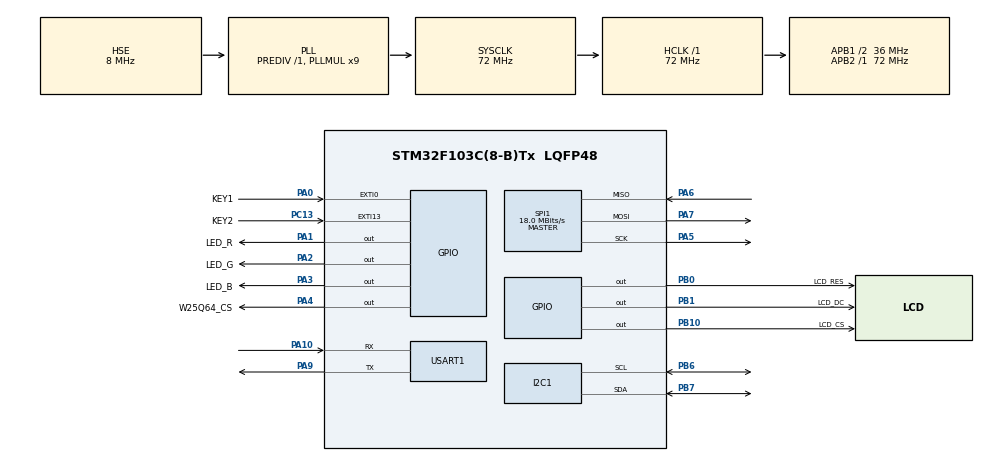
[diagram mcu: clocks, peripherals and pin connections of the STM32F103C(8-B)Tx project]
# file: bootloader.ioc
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Dma.Request0=SPI1_RX
Dma.Request1=SPI1_TX
Dma.SPI1_RX.0.Direction=DMA_PERIPH_TO_MEMORY
Dma.SPI1_RX.0.Instance=DMA1_Channel2
Dma.SPI1_RX.0.MemDataAlignment=DMA_MDATAALIGN_BYTE
Dma.SPI1_RX.0.MemInc=DMA_MINC_ENABLE
Dma.SPI1_RX.0.Mode=DMA_NORMAL
Dma.SPI1_RX.0.PeriphDataAlignment=DMA_PDATAALIGN_BYTE
Dma.SPI1_RX.0.PeriphInc=DMA_PINC_DISABLE
Dma.SPI1_RX.0.Priority=DMA_PRIORITY_LOW
Dma.SPI1_TX.1.Direction=DMA_MEMORY_TO_PERIPH
Dma.SPI1_TX.1.Instance=DMA1_Channel3
Dma.SPI1_TX.1.MemDataAlignment=DMA_MDATAALIGN_BYTE
Dma.SPI1_TX.1.MemInc=DMA_MINC_ENABLE
Dma.SPI1_TX.1.Mode=DMA_NORMAL
Dma.SPI1_TX.1.PeriphDataAlignment=DMA_PDATAALIGN_BYTE
Dma.SPI1_TX.1.PeriphInc=DMA_PINC_DISABLE
Dma.SPI1_TX.1.Priority=DMA_PRIORITY_LOW
Mcu.Family=STM32F1
Mcu.Name=STM32F103C(8-B)Tx
Mcu.Package=LQFP48
NVIC.DMA1_Channel2_IRQn=true\:0\:0\:false\:false\:true\:false\:true\:true
NVIC.DMA1_Channel3_IRQn=true\:0\:0\:false\:false\:true\:false\:true\:true
NVIC.EXTI0_IRQn=true\:0\:0\:false\:false\:true\:true\:true\:true
NVIC.EXTI15_10_IRQn=true\:0\:0\:false\:false\:true\:true\:true\:true
NVIC.PriorityGroup=NVIC_PRIORITYGROUP_4
NVIC.SPI1_IRQn=true\:0\:0\:false\:false\:true\:true\:true\:true
NVIC.USART1_IRQn=true\:0\:0\:false\:false\:true\:true\:true\:true
PA0-WKUP.GPIO_Label=KEY1
PA0-WKUP.Signal=GPXTI0
PA1.GPIO_Label=LED_R
PA1.GPIO_PuPd=GPIO_NOPULL
PA1.GPIO_Speed=GPIO_SPEED_FREQ_LOW
PA1.PinState=GPIO_PIN_SET
PA1.Signal=GPIO_Output
PA10.Mode=Asynchronous
PA10.Signal=USART1_RX
PA13.Mode=Serial_Wire
PA13.Signal=SYS_JTMS-SWDIO
PA14.Mode=Serial_Wire
PA14.Signal=SYS_JTCK-SWCLK
PA2.GPIO_Label=LED_G
PA2.PinState=GPIO_PIN_SET
PA2.Signal=GPIO_Output
PA3.GPIO_Label=LED_B
PA3.PinState=GPIO_PIN_SET
PA3.Signal=GPIO_Output
PA4.GPIO_Label=W25Q64_CS
PA4.GPIO_Speed=GPIO_SPEED_FREQ_HIGH
PA4.PinState=GPIO_PIN_SET
PA4.Signal=GPIO_Output
PA5.Mode=Full_Duplex_Master
PA5.Signal=SPI1_SCK
PA6.Mode=Full_Duplex_Master
PA6.Signal=SPI1_MISO
PA7.Mode=Full_Duplex_Master
PA7.Signal=SPI1_MOSI
PA9.Mode=Asynchronous
PA9.Signal=USART1_TX
PB0.GPIO_Label=LCD_RES
PB0.Signal=GPIO_Output
PB1.GPIO_Label=LCD_DC
PB1.Signal=GPIO_Output
PB10.GPIO_Label=LCD_CS
PB10.GPIO_Speed=GPIO_SPEED_FREQ_HIGH
PB10.PinState=GPIO_PIN_SET
PB10.Signal=GPIO_Output
PB6.Mode=I2C
PB6.Signal=I2C1_SCL
PB7.Mode=I2C
PB7.Signal=I2C1_SDA
PC13-TAMPER-RTC.GPIO_Label=KEY2
PC13-TAMPER-RTC.Signal=GPXTI13
PC14-OSC32_IN.Mode=LSE-External-Oscillator
PC14-OSC32_IN.Signal=RCC_OSC32_IN
PC15-OSC32_OUT.Mode=LSE-External-Oscillator
PC15-OSC32_OUT.Signal=RCC_OSC32_OUT
PD0-OSC_IN.Mode=HSE-External-Oscillator
PD0-OSC_IN.Signal=RCC_OSC_IN
PD1-OSC_OUT.Mode=HSE-External-Oscillator
PD1-OSC_OUT.Signal=RCC_OSC_OUT
ProjectManager.HeapSize=0x200
ProjectManager.StackSize=0x400
ProjectManager.TargetToolchain=MDK-ARM V5.32
RCC.AHBFreq_Value=72000000
RCC.APB1CLKDivider=RCC_HCLK_DIV2
RCC.APB1Freq_Value=36000000
RCC.APB1TimFreq_Value=72000000
RCC.APB2Freq_Value=72000000
RCC.APB2TimFreq_Value=72000000
RCC.HCLKFreq_Value=72000000
RCC.PLLMUL=RCC_PLL_MUL9
RCC.PLLSourceVirtual=RCC_PLLSOURCE_HSE
RCC.SYSCLKFreq_VALUE=72000000
RCC.SYSCLKSource=RCC_SYSCLKSOURCE_PLLCLK
RCC.USBFreq_Value=72000000
SPI1.BaudRatePrescaler=SPI_BAUDRATEPRESCALER_4
SPI1.CalculateBaudRate=18.0 MBits/s
SPI1.Direction=SPI_DIRECTION_2LINES
SPI1.Mode=SPI_MODE_MASTER
SPI1.VirtualType=VM_MASTER
USART1.VirtualMode=VM_ASYNC
board=custom

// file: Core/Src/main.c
/* USER CODE BEGIN Header */
/**
 ******************************************************************************
 * @file           : main.c
 * @brief          : Main program body
 ******************************************************************************
 * @attention
 *
 * Copyright (c) 2026 STMicroelectronics.
 * All rights reserved.
 *
 * This software is licensed under terms that can be found in the LICENSE file
 * in the root directory of this software component.
 * If no LICENSE file comes with this software, it is provided AS-IS.
 *
 ******************************************************************************
 */
/* USER CODE END Header */
#include "main.h"
#include "i2c.h"
#include "spi.h"
#include "usart.h"
#include "gpio.h"

/* USER CODE BEGIN Includes */
#include "w25q64.h"
#include "App_bootloader.h"
/* USER CODE END Includes */

void SystemClock_Config(void);

int main(void)
{

  /* MCU Configuration--------------------------------------------------------*/

  /* Reset of all peripherals, Initializes the Flash interface and the Systick. */
  HAL_Init();

  /* Configure the system clock */
  SystemClock_Config();

  /* Initialize all configured peripherals */
  MX_GPIO_Init();
  MX_USART1_UART_Init();
  Boot_StartUartIap(); /* 提前启动UART DMA，按键等待期间可检测OTA帧 */
  MX_I2C1_Init();
  MX_SPI1_Init();
  /* USER CODE BEGIN 2 */

  // 1. 检查是否需要更新
  App_bootloader_check_update();

  // 2. 等待3秒
  App_bootloader_check_default();

  // 3. 更新程序
  App_bootloader_update();

  // 4. 复制到运行区并跳转
  App_bootloader_copy_and_jump();

  /* USER CODE END 2 */

  /* Infinite loop */
  while (1)
  {

  }
}

void SystemClock_Config(void)
{
  RCC_OscInitTypeDef RCC_OscInitStruct = {0};
  RCC_ClkInitTypeDef RCC_ClkInitStruct = {0};

  /** Initializes the RCC Oscillators according to the specified parameters
   * in the RCC_OscInitTypeDef structure.
   */
  RCC_OscInitStruct.OscillatorType = RCC_OSCILLATORTYPE_HSE;
  RCC_OscInitStruct.HSEState = RCC_HSE_ON;
  RCC_OscInitStruct.HSEPredivValue = RCC_HSE_PREDIV_DIV1;
  RCC_OscInitStruct.HSIState = RCC_HSI_ON;
  RCC_OscInitStruct.PLL.PLLState = RCC_PLL_ON;
  RCC_OscInitStruct.PLL.PLLSource = RCC_PLLSOURCE_HSE;
  RCC_OscInitStruct.PLL.PLLMUL = RCC_PLL_MUL9;
  if (HAL_RCC_OscConfig(&RCC_OscInitStruct) != HAL_OK)
  {
    Error_Handler();
  }

  /** Initializes the CPU, AHB and APB buses clocks
   */
  RCC_ClkInitStruct.ClockType = RCC_CLOCKTYPE_HCLK | RCC_CLOCKTYPE_SYSCLK | RCC_CLOCKTYPE_PCLK1 | RCC_CLOCKTYPE_PCLK2;
  RCC_ClkInitStruct.SYSCLKSource = RCC_SYSCLKSOURCE_PLLCLK;
  RCC_ClkInitStruct.AHBCLKDivider = RCC_SYSCLK_DIV1;
  RCC_ClkInitStruct.APB1CLKDivider = RCC_HCLK_DIV2;
  RCC_ClkInitStruct.APB2CLKDivider = RCC_HCLK_DIV1;

  if (HAL_RCC_ClockConfig(&RCC_ClkInitStruct, FLASH_LATENCY_2) != HAL_OK)
  {
    Error_Handler();
  }
}

void Error_Handler(void)
{
  __disable_irq();
  while (1)
  {
  }
}
